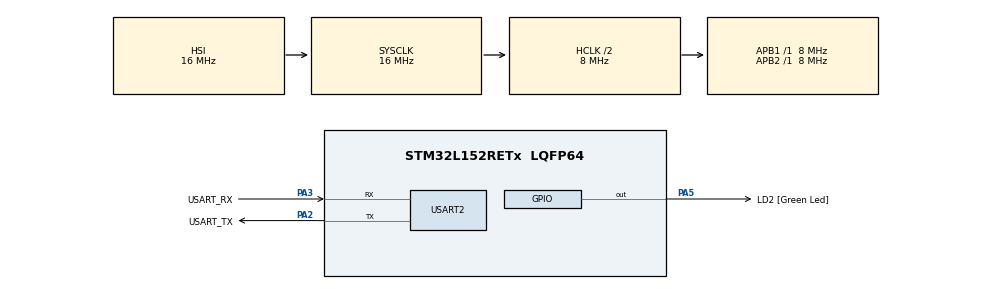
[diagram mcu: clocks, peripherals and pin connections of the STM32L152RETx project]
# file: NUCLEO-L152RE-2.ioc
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Mcu.Family=STM32L1
Mcu.Name=STM32L152RETx
Mcu.Package=LQFP64
NVIC.PriorityGroup=NVIC_PRIORITYGROUP_0
PA13.Mode=Serial_Wire
PA13.Signal=SYS_JTMS-SWDIO
PA14.Mode=Serial_Wire
PA14.Signal=SYS_JTCK-SWCLK
PA2.GPIO_Label=USART_TX
PA2.Mode=Asynchronous
PA2.Signal=USART2_TX
PA3.GPIO_Label=USART_RX
PA3.Mode=Asynchronous
PA3.Signal=USART2_RX
PA5.GPIO_Label=LD2 [Green Led]
PA5.Signal=GPIO_Output
PB3.GPIO_Label=SWO
PB3.Signal=SYS_JTDO-TRACESWO
PC14-OSC32_IN.Mode=LSE-External-Oscillator
PC14-OSC32_IN.Signal=RCC_OSC32_IN
PC15-OSC32_OUT.Mode=LSE-External-Oscillator
PC15-OSC32_OUT.Signal=RCC_OSC32_OUT
ProjectManager.HeapSize=0x200
ProjectManager.StackSize=0x400
ProjectManager.TargetToolchain=STM32CubeIDE
RCC.48MHZClocksFreq_Value=24000000
RCC.AHBCLKDivider=RCC_SYSCLK_DIV2
RCC.AHBFreq_Value=8000000
RCC.APB1Freq_Value=8000000
RCC.APB1TimFreq_Value=8000000
RCC.APB2Freq_Value=8000000
RCC.APB2TimFreq_Value=8000000
RCC.HCLKFreq_Value=8000000
RCC.HSE_VALUE=8000000
RCC.HSI_VALUE=16000000
RCC.MSIClockRange=RCC_MSIRANGE_6
RCC.MSI_VALUE=4194000
RCC.RTCClockSelectionVirtual=RCC_RTCCLKSOURCE_LSE
RCC.SYSCLKFreq_VALUE=16000000
RCC.SYSCLKSource=RCC_SYSCLKSOURCE_HSI
RCC.USBOutput=48000000
RCC.VCOOutputFreq_Value=48000000
USART2.VirtualMode=VM_ASYNC
board=NUCLEO-L152RE

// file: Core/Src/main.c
/* USER CODE BEGIN Header */
/**
  ******************************************************************************
  * @file           : main.c
  * @brief          : Main program body
  ******************************************************************************
  * @attention
  *
  * <h2><center>&copy; Copyright (c) 2019 STMicroelectronics.
  * All rights reserved.</center></h2>
  *
  * This software component is licensed by ST under BSD 3-Clause license,
  * the "License"; You may not use this file except in compliance with the
  * License. You may obtain a copy of the License at:
  *                        opensource.org/licenses/BSD-3-Clause
  *
  ******************************************************************************
  */
/* USER CODE END Header */

#include "main.h"

/* USER CODE BEGIN Includes */
#include <stdio.h>
#include <string.h>
/* USER CODE END Includes */

UART_HandleTypeDef huart2;

void SystemClock_Config(void);
static void MX_GPIO_Init(void);
static void MX_USART2_UART_Init(void);

/* USER CODE BEGIN 0 */
char test[]="Hello World L152RE\n";
/* USER CODE END 0 */

int main(void)
{

  /* MCU Configuration--------------------------------------------------------*/

  /* Reset of all peripherals, Initializes the Flash interface and the Systick. */
  HAL_Init();

  /* Configure the system clock */
  SystemClock_Config();

  /* Initialize all configured peripherals */
  MX_GPIO_Init();
  MX_USART2_UART_Init();

  /* Infinite loop */
  /* USER CODE BEGIN WHILE */

  while (1)
  {
	  HAL_GPIO_TogglePin(LD2_GPIO_Port, LD2_Pin);
	  HAL_Delay(2000);
	  printf("run\n");
	  HAL_UART_Transmit(&huart2, (uint8_t *)test,strlen(test),100);
    /* USER CODE END WHILE */

  }
}

void SystemClock_Config(void)
{
  RCC_OscInitTypeDef RCC_OscInitStruct = {0};
  RCC_ClkInitTypeDef RCC_ClkInitStruct = {0};

  /** Configure the main internal regulator output voltage
  */
  __HAL_PWR_VOLTAGESCALING_CONFIG(PWR_REGULATOR_VOLTAGE_SCALE1);
  /** Initializes the CPU, AHB and APB busses clocks
  */
  RCC_OscInitStruct.OscillatorType = RCC_OSCILLATORTYPE_HSI;
  RCC_OscInitStruct.HSIState = RCC_HSI_ON;
  RCC_OscInitStruct.HSICalibrationValue = RCC_HSICALIBRATION_DEFAULT;
  RCC_OscInitStruct.PLL.PLLState = RCC_PLL_NONE;
  if (HAL_RCC_OscConfig(&RCC_OscInitStruct) != HAL_OK)
  {
    Error_Handler();
  }
  /** Initializes the CPU, AHB and APB busses clocks
  */
  RCC_ClkInitStruct.ClockType = RCC_CLOCKTYPE_HCLK|RCC_CLOCKTYPE_SYSCLK
                              |RCC_CLOCKTYPE_PCLK1|RCC_CLOCKTYPE_PCLK2;
  RCC_ClkInitStruct.SYSCLKSource = RCC_SYSCLKSOURCE_HSI;
  RCC_ClkInitStruct.AHBCLKDivider = RCC_SYSCLK_DIV2;
  RCC_ClkInitStruct.APB1CLKDivider = RCC_HCLK_DIV1;
  RCC_ClkInitStruct.APB2CLKDivider = RCC_HCLK_DIV1;

  if (HAL_RCC_ClockConfig(&RCC_ClkInitStruct, FLASH_LATENCY_0) != HAL_OK)
  {
    Error_Handler();
  }
}

static void MX_USART2_UART_Init(void)
{

  huart2.Instance = USART2;
  huart2.Init.BaudRate = 115200;
  huart2.Init.WordLength = UART_WORDLENGTH_8B;
  huart2.Init.StopBits = UART_STOPBITS_1;
  huart2.Init.Parity = UART_PARITY_NONE;
  huart2.Init.Mode = UART_MODE_TX_RX;
  huart2.Init.HwFlowCtl = UART_HWCONTROL_NONE;
  huart2.Init.OverSampling = UART_OVERSAMPLING_16;
  if (HAL_UART_Init(&huart2) != HAL_OK)
  {
    Error_Handler();
  }

}

static void MX_GPIO_Init(void)
{
  GPIO_InitTypeDef GPIO_InitStruct = {0};

  /* GPIO Ports Clock Enable */
  __HAL_RCC_GPIOC_CLK_ENABLE();
  __HAL_RCC_GPIOA_CLK_ENABLE();
  __HAL_RCC_GPIOB_CLK_ENABLE();

  /*Configure GPIO pin Output Level */
  HAL_GPIO_WritePin(LD2_GPIO_Port, LD2_Pin, GPIO_PIN_RESET);

  /*Configure GPIO pin : LD2_Pin */
  GPIO_InitStruct.Pin = LD2_Pin;
  GPIO_InitStruct.Mode = GPIO_MODE_OUTPUT_PP;
  GPIO_InitStruct.Pull = GPIO_NOPULL;
  GPIO_InitStruct.Speed = GPIO_SPEED_FREQ_LOW;
  HAL_GPIO_Init(LD2_GPIO_Port, &GPIO_InitStruct);

}

/* USER CODE BEGIN 4 */
int __io_putchar(int ch) {
ITM_SendChar( ch );
return ( ch );
}
/* USER CODE END 4 */

void Error_Handler(void)
{
}

/************************ (C) COPYRIGHT STMicroelectronics *****END OF FILE****/
